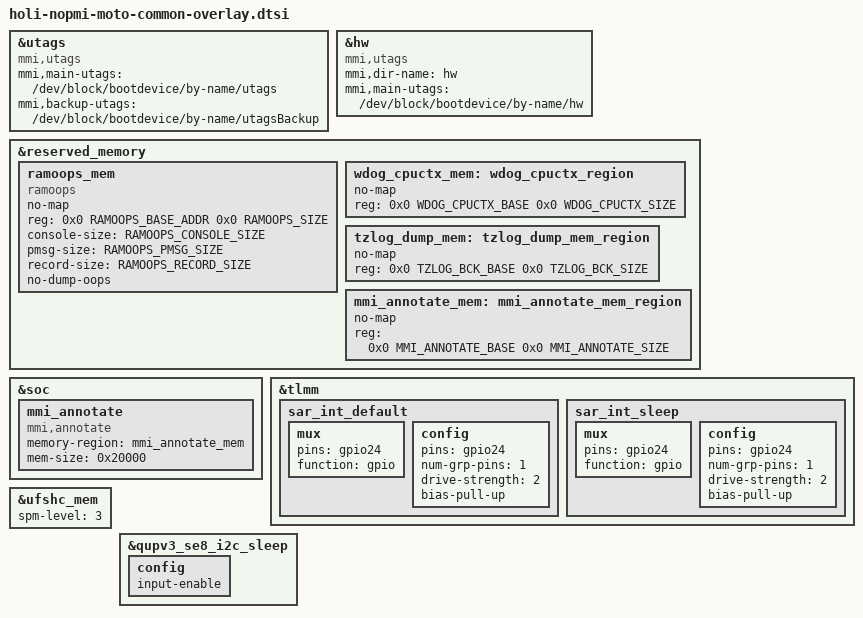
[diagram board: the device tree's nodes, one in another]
/* Copyright (c) 2020, The Linux Foundation. All rights reserved.
 *
 * This program is free software; you can redistribute it and/or modify
 * it under the terms of the GNU General Public License version 2 and
 * only version 2 as published by the Free Software Foundation.
 *
 * This program is distributed in the hope that it will be useful,
 * but WITHOUT ANY WARRANTY; without even the implied warranty of
 * MERCHANTABILITY or FITNESS FOR A PARTICULAR PURPOSE.  See the
 * GNU General Public License for more details.
 */
#include "holi-pm6125-overlay.dtsi"
#include "holi-regulators-pm6125.dtsi"
#include "carrier-channel-ids.dtsi"
#include <dt-bindings/moto/moto-mem-reserve.h>

&utags {
	compatible = "mmi,utags";
	mmi,main-utags = "/dev/block/bootdevice/by-name/utags";
	mmi,backup-utags = "/dev/block/bootdevice/by-name/utagsBackup";
};

&hw {
	compatible = "mmi,utags";
	mmi,dir-name = "hw";
	mmi,main-utags = "/dev/block/bootdevice/by-name/hw";
};

&reserved_memory {
	ramoops_mem {
		compatible = "ramoops";
		no-map;
		reg = <0x0 RAMOOPS_BASE_ADDR 0x0 RAMOOPS_SIZE>;
		console-size = <RAMOOPS_CONSOLE_SIZE>;
		pmsg-size = <RAMOOPS_PMSG_SIZE>;
		record-size = <RAMOOPS_RECORD_SIZE>;
		no-dump-oops;
	};

	wdog_cpuctx_mem: wdog_cpuctx_region {
		no-map;
		reg = <0x0 WDOG_CPUCTX_BASE
				0x0 WDOG_CPUCTX_SIZE>;
	};

	tzlog_dump_mem: tzlog_dump_mem_region {
		no-map;
		reg = <0x0  TZLOG_BCK_BASE
				0x0 TZLOG_BCK_SIZE>;
	};

	mmi_annotate_mem: mmi_annotate_mem_region {
		no-map;
		reg = <0x0  MMI_ANNOTATE_BASE
				0x0 MMI_ANNOTATE_SIZE>;
	};
};

&soc {
	mmi_annotate {
		compatible = "mmi,annotate";
		memory-region = <&mmi_annotate_mem>;
		mem-size = <0x20000>;
	};
};

&tlmm {
	sar_int_default: sar_int_default {
			mux {
				pins = "gpio24";
				function =  "gpio";
			};
			config {
				pins = "gpio24";
				num-grp-pins = <1>;
				drive-strength = <2>;
				bias-pull-up;
			};
	};

	sar_int_sleep: sar_int_sleep {
			mux {
				pins = "gpio24";
				function =  "gpio";
			};
			config {
				pins = "gpio24";
				num-grp-pins = <1>;
				drive-strength = <2>;
				bias-pull-up;
			};
	};
};

&ufshc_mem {
	spm-level = <3>;
};

&qupv3_se8_i2c_sleep {
    config {
        input-enable;
    };
};
